AUTOSAR XML (schema 4-2-2)
package /STELLANTIS/EPT/ASWCs
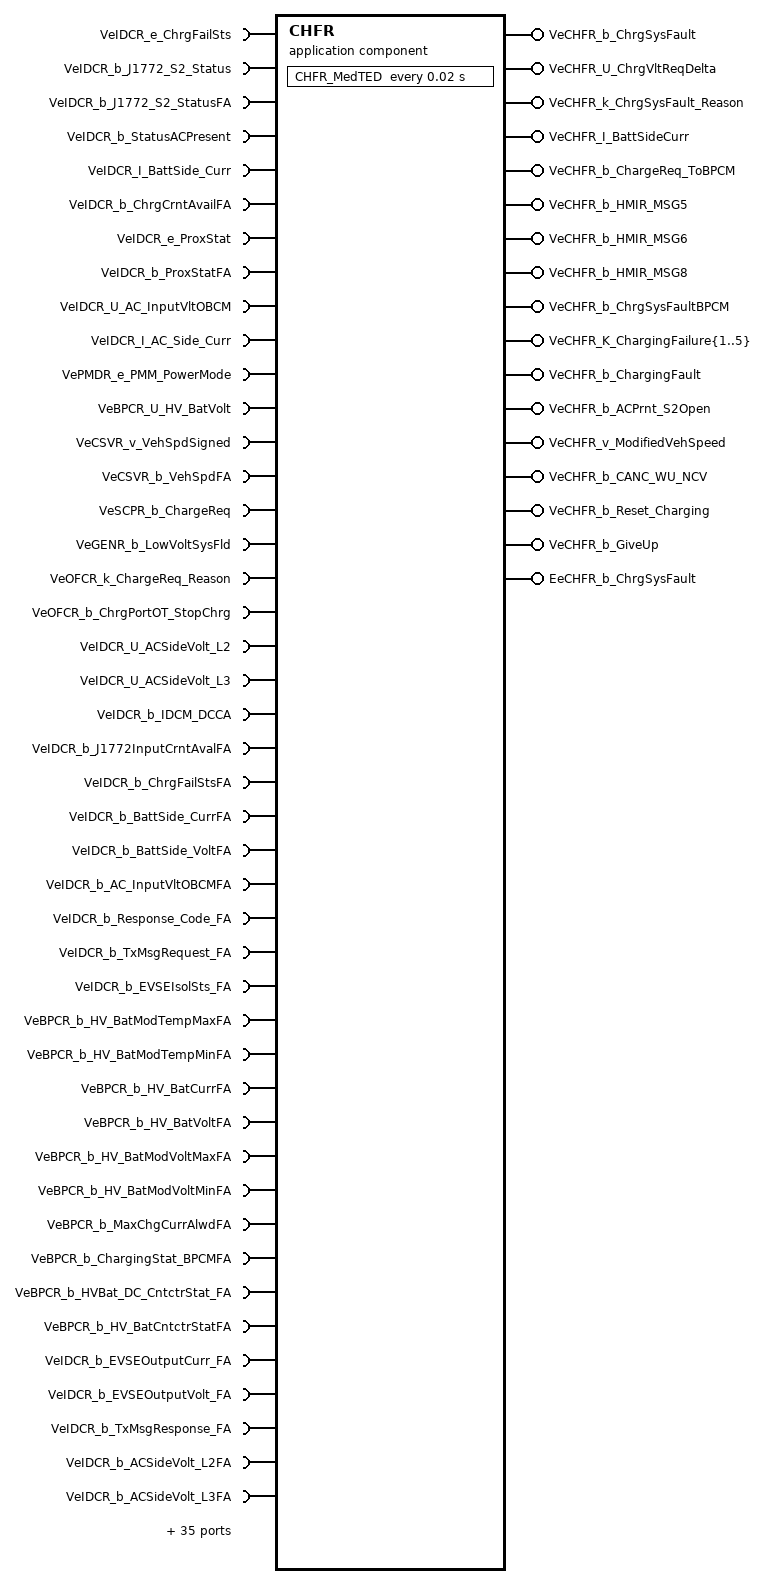
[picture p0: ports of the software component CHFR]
  application sw component type CHFR
    78 x require port:
      VeIDCR_e_ChrgFailSts: variation-point={short-label=vpVeIDCR_e_ChrgFailSts, sw-syscond=1}, nonqueued-receiver-com-spec{data-element=Value, init-value=CeOBCR_e_No_FLT}, required-interface=VeIDCR_e_ChrgFailSts
      VeIDCR_b_J1772_S2_Status: variation-point={short-label=vpVeIDCR_b_J1772_S2_Status, sw-syscond=1}, nonqueued-receiver-com-spec{data-element=Value, init-value=0}, required-interface=VeIDCR_b_J1772_S2_Status
      VeIDCR_b_J1772_S2_StatusFA: variation-point={short-label=vpVeIDCR_b_J1772_S2_StatusFA, sw-syscond=1}, nonqueued-receiver-com-spec{data-element=Value, init-value=0}, required-interface=VeIDCR_b_J1772_S2_StatusFA
      VeIDCR_b_StatusACPresent: variation-point={short-label=vpVeIDCR_b_StatusACPresent, sw-syscond=1}, nonqueued-receiver-com-spec{data-element=Value, init-value=0}, required-interface=VeIDCR_b_StatusACPresent
      VeIDCR_I_BattSide_Curr: variation-point={short-label=vpVeIDCR_I_BattSide_Curr, sw-syscond=1}, nonqueued-receiver-com-spec{data-element=Value, init-value=0}, required-interface=VeIDCR_I_BattSide_Curr
      VeIDCR_b_ChrgCrntAvailFA: variation-point={short-label=vpVeIDCR_b_ChrgCrntAvailFA, sw-syscond=1}, nonqueued-receiver-com-spec{data-element=Value, init-value=0}, required-interface=VeIDCR_b_ChrgCrntAvailFA
      VeIDCR_e_ProxStat: variation-point={short-label=vpVeIDCR_e_ProxStat, sw-syscond=1}, nonqueued-receiver-com-spec{data-element=Value, init-value=CeOBCR_e_ProxLo_OBCM}, required-interface=VeIDCR_e_ProxStat
      VeIDCR_b_ProxStatFA: variation-point={short-label=vpVeIDCR_b_ProxStatFA, sw-syscond=1}, nonqueued-receiver-com-spec{data-element=Value, init-value=0}, required-interface=VeIDCR_b_ProxStatFA
      VeIDCR_U_AC_InputVltOBCM: variation-point={short-label=vpVeIDCR_U_AC_InputVltOBCM, sw-syscond=1}, nonqueued-receiver-com-spec{data-element=Value, init-value=0}, required-interface=VeIDCR_U_AC_InputVltOBCM
      VeIDCR_I_AC_Side_Curr: variation-point={short-label=vpVeIDCR_I_AC_Side_Curr, sw-syscond=1}, nonqueued-receiver-com-spec{data-element=Value, init-value=0}, required-interface=VeIDCR_I_AC_Side_Curr
      VePMDR_e_PMM_PowerMode: variation-point={short-label=vpVePMDR_e_PMM_PowerMode, sw-syscond=1}, nonqueued-receiver-com-spec{data-element=Value, init-value=CePMDR_e_PowerMode_Off}, required-interface=VePMDR_e_PMM_PowerMode
      VeBPCR_U_HV_BatVolt: variation-point={short-label=vpVeBPCR_U_HV_BatVolt, sw-syscond=1}, nonqueued-receiver-com-spec{data-element=Value, init-value=0}, required-interface=VeBPCR_U_HV_BatVolt
      VeCSVR_v_VehSpdSigned: variation-point={short-label=vpVeCSVR_v_VehSpdSigned, sw-syscond=1}, nonqueued-receiver-com-spec{data-element=Value, init-value=0}, required-interface=VeCSVR_v_VehSpdSigned
      VeCSVR_b_VehSpdFA: variation-point={short-label=vpVeCSVR_b_VehSpdFA, sw-syscond=1}, nonqueued-receiver-com-spec{data-element=Value, init-value=0}, required-interface=VeCSVR_b_VehSpdFA
      VeSCPR_b_ChargeReq: variation-point={short-label=vpVeSCPR_b_ChargeReq, sw-syscond=1}, nonqueued-receiver-com-spec{data-element=Value, init-value=0}, required-interface=VeSCPR_b_ChargeReq
      VeGENR_b_LowVoltSysFld: variation-point={short-label=vpVeGENR_b_LowVoltSysFld, sw-syscond=1}, nonqueued-receiver-com-spec{data-element=Value, init-value=0}, required-interface=VeGENR_b_LowVoltSysFld
      VeOFCR_k_ChargeReq_Reason: variation-point={short-label=vpVeOFCR_k_ChargeReq_Reason, sw-syscond=1}, nonqueued-receiver-com-spec{data-element=Value, init-value=0}, required-interface=VeOFCR_k_ChargeReq_Reason
      VeOFCR_b_ChrgPortOT_StopChrg: variation-point={short-label=vpVeOFCR_b_ChrgPortOT_StopChrg, sw-syscond=1}, nonqueued-receiver-com-spec{data-element=Value, init-value=0}, required-interface=VeOFCR_b_ChrgPortOT_StopChrg
      VeIDCR_U_ACSideVolt_L2: variation-point={short-label=vpVeIDCR_U_ACSideVolt_L2, sw-syscond=1}, nonqueued-receiver-com-spec{data-element=Value, init-value=0}, required-interface=VeIDCR_U_ACSideVolt_L2
      VeIDCR_U_ACSideVolt_L3: variation-point={short-label=vpVeIDCR_U_ACSideVolt_L3, sw-syscond=1}, nonqueued-receiver-com-spec{data-element=Value, init-value=0}, required-interface=VeIDCR_U_ACSideVolt_L3
      VeIDCR_b_IDCM_DCCA: variation-point={short-label=vpVeIDCR_b_IDCM_DCCA, sw-syscond=1}, nonqueued-receiver-com-spec{data-element=Value, init-value=0}, required-interface=VeIDCR_b_IDCM_DCCA
      VeIDCR_b_J1772InputCrntAvalFA: variation-point={short-label=vpVeIDCR_b_J1772InputCrntAvalFA, sw-syscond=1}, nonqueued-receiver-com-spec{data-element=Value, init-value=0}, required-interface=VeIDCR_b_J1772InputCrntAvalFA
      VeIDCR_b_ChrgFailStsFA: variation-point={short-label=vpVeIDCR_b_ChrgFailStsFA, sw-syscond=1}, nonqueued-receiver-com-spec{data-element=Value, init-value=0}, required-interface=VeIDCR_b_ChrgFailStsFA
      VeIDCR_b_BattSide_CurrFA: variation-point={short-label=vpVeIDCR_b_BattSide_CurrFA, sw-syscond=1}, nonqueued-receiver-com-spec{data-element=Value, init-value=0}, required-interface=VeIDCR_b_BattSide_CurrFA
      VeIDCR_b_BattSide_VoltFA: variation-point={short-label=vpVeIDCR_b_BattSide_VoltFA, sw-syscond=1}, nonqueued-receiver-com-spec{data-element=Value, init-value=0}, required-interface=VeIDCR_b_BattSide_VoltFA
      VeIDCR_b_AC_InputVltOBCMFA: variation-point={short-label=vpVeIDCR_b_AC_InputVltOBCMFA, sw-syscond=1}, nonqueued-receiver-com-spec{data-element=Value, init-value=0}, required-interface=VeIDCR_b_AC_InputVltOBCMFA
      VeIDCR_b_Response_Code_FA: variation-point={short-label=vpVeIDCR_b_Response_Code_FA, sw-syscond=1}, nonqueued-receiver-com-spec{data-element=Value, init-value=0}, required-interface=VeIDCR_b_Response_Code_FA
      VeIDCR_b_TxMsgRequest_FA: variation-point={short-label=vpVeIDCR_b_TxMsgRequest_FA, sw-syscond=1}, nonqueued-receiver-com-spec{data-element=Value, init-value=0}, required-interface=VeIDCR_b_TxMsgRequest_FA
      VeIDCR_b_EVSEIsolSts_FA: variation-point={short-label=vpVeIDCR_b_EVSEIsolSts_FA, sw-syscond=1}, nonqueued-receiver-com-spec{data-element=Value, init-value=0}, required-interface=VeIDCR_b_EVSEIsolSts_FA
      VeBPCR_b_HV_BatModTempMaxFA: variation-point={short-label=vpVeBPCR_b_HV_BatModTempMaxFA, sw-syscond=1}, nonqueued-receiver-com-spec{data-element=Value, init-value=0}, required-interface=VeBPCR_b_HV_BatModTempMaxFA
      VeBPCR_b_HV_BatModTempMinFA: variation-point={short-label=vpVeBPCR_b_HV_BatModTempMinFA, sw-syscond=1}, nonqueued-receiver-com-spec{data-element=Value, init-value=0}, required-interface=VeBPCR_b_HV_BatModTempMinFA
      VeBPCR_b_HV_BatCurrFA: variation-point={short-label=vpVeBPCR_b_HV_BatCurrFA, sw-syscond=1}, nonqueued-receiver-com-spec{data-element=Value, init-value=0}, required-interface=VeBPCR_b_HV_BatCurrFA
      VeBPCR_b_HV_BatVoltFA: variation-point={short-label=vpVeBPCR_b_HV_BatVoltFA, sw-syscond=1}, nonqueued-receiver-com-spec{data-element=Value, init-value=0}, required-interface=VeBPCR_b_HV_BatVoltFA
      VeBPCR_b_HV_BatModVoltMaxFA: variation-point={short-label=vpVeBPCR_b_HV_BatModVoltMaxFA, sw-syscond=1}, nonqueued-receiver-com-spec{data-element=Value, init-value=0}, required-interface=VeBPCR_b_HV_BatModVoltMaxFA
      VeBPCR_b_HV_BatModVoltMinFA: variation-point={short-label=vpVeBPCR_b_HV_BatModVoltMinFA, sw-syscond=1}, nonqueued-receiver-com-spec{data-element=Value, init-value=0}, required-interface=VeBPCR_b_HV_BatModVoltMinFA
      VeBPCR_b_MaxChgCurrAlwdFA: variation-point={short-label=vpVeBPCR_b_MaxChgCurrAlwdFA, sw-syscond=1}, nonqueued-receiver-com-spec{data-element=Value, init-value=0}, required-interface=VeBPCR_b_MaxChgCurrAlwdFA
      VeBPCR_b_ChargingStat_BPCMFA: variation-point={short-label=vpVeBPCR_b_ChargingStat_BPCMFA, sw-syscond=1}, nonqueued-receiver-com-spec{data-element=Value, init-value=0}, required-interface=VeBPCR_b_ChargingStat_BPCMFA
      VeBPCR_b_HVBat_DC_CntctrStat_FA: variation-point={short-label=vpVeBPCR_b_HVBat_DC_CntctrStat_FA, sw-syscond=1}, nonqueued-receiver-com-spec{data-element=Value, init-value=0}, required-interface=VeBPCR_b_HVBat_DC_CntctrStat_FA
      VeBPCR_b_HV_BatCntctrStatFA: variation-point={short-label=vpVeBPCR_b_HV_BatCntctrStatFA, sw-syscond=1}, nonqueued-receiver-com-spec{data-element=Value, init-value=0}, required-interface=VeBPCR_b_HV_BatCntctrStatFA
      VeIDCR_b_EVSEOutputCurr_FA: variation-point={short-label=vpVeIDCR_b_EVSEOutputCurr_FA, sw-syscond=1}, nonqueued-receiver-com-spec{data-element=Value, init-value=0}, required-interface=VeIDCR_b_EVSEOutputCurr_FA
      VeIDCR_b_EVSEOutputVolt_FA: variation-point={short-label=vpVeIDCR_b_EVSEOutputVolt_FA, sw-syscond=1}, nonqueued-receiver-com-spec{data-element=Value, init-value=0}, required-interface=VeIDCR_b_EVSEOutputVolt_FA
      VeIDCR_b_TxMsgResponse_FA: variation-point={short-label=vpVeIDCR_b_TxMsgResponse_FA, sw-syscond=1}, nonqueued-receiver-com-spec{data-element=Value, init-value=0}, required-interface=VeIDCR_b_TxMsgResponse_FA
      VeIDCR_b_ACSideVolt_L2FA: variation-point={short-label=vpVeIDCR_b_ACSideVolt_L2FA, sw-syscond=1}, nonqueued-receiver-com-spec{data-element=Value, init-value=0}, required-interface=VeIDCR_b_ACSideVolt_L2FA
      VeIDCR_b_ACSideVolt_L3FA: variation-point={short-label=vpVeIDCR_b_ACSideVolt_L3FA, sw-syscond=1}, nonqueued-receiver-com-spec{data-element=Value, init-value=0}, required-interface=VeIDCR_b_ACSideVolt_L3FA
      VeIDCR_e_V2L_DischargeFailSts: variation-point={short-label=vpVeIDCR_e_V2L_DischargeFailSts, sw-syscond=1}, nonqueued-receiver-com-spec{data-element=Value, init-value=CeVTLR_e_No_Fault}, required-interface=VeIDCR_e_V2L_DischargeFailSts
      VeIDCR_b_V2L_DischargeFailStsFA: variation-point={short-label=vpVeIDCR_b_V2L_DischargeFailStsFA, sw-syscond=1}, nonqueued-receiver-com-spec{data-element=Value, init-value=0}, required-interface=VeIDCR_b_V2L_DischargeFailStsFA
      VeDMAB_y_StatusByte_CtrlPilotCkt: variation-point={short-label=vpVeDMAB_y_StatusByte_CtrlPilotCkt, sw-syscond=1}, nonqueued-receiver-com-spec{data-element=Value, init-value=0}, required-interface=VeDMAB_y_StatusByte_CtrlPilotCkt
      VeDMAB_y_StatusByte_LosCommBECM_A_CANC11: variation-point={short-label=vpVeDMAB_y_StatusByte_LosCommBECM_A_CANC11, sw-syscond=1}, nonqueued-receiver-com-spec{data-element=Value, init-value=0}, required-interface=VeDMAB_y_StatusByte_LosCommBECM_A_CANC11
      VeDMAB_y_StatusByte_LosCommBECM_A: variation-point={short-label=vpVeDMAB_y_StatusByte_LosCommBECM_A, sw-syscond=1}, nonqueued-receiver-com-spec{data-element=Value, init-value=0}, required-interface=VeDMAB_y_StatusByte_LosCommBECM_A
      VeBPCR_b_DCIsolStsFA: variation-point={short-label=vpVeBPCR_b_DCIsolStsFA, sw-syscond=1}, nonqueued-receiver-com-spec{data-element=Value, init-value=0}, required-interface=VeBPCR_b_DCIsolStsFA
      VeBPCR_b_HV_SeriesVoltFA: variation-point={short-label=vpVeBPCR_b_HV_SeriesVoltFA, sw-syscond=1}, nonqueued-receiver-com-spec{data-element=Value, init-value=0}, required-interface=VeBPCR_b_HV_SeriesVoltFA
      VeBPCR_b_HV_AuxLoadOffReqFA: variation-point={short-label=vpVeBPCR_b_HV_AuxLoadOffReqFA, sw-syscond=1}, nonqueued-receiver-com-spec{data-element=Value, init-value=0}, required-interface=VeBPCR_b_HV_AuxLoadOffReqFA
      VaHPMR_K_RsnForUnintndShtDwn1: variation-point={short-label=vpVaHPMR_K_RsnForUnintndShtDwn1, sw-syscond=1}, nonqueued-receiver-com-spec{data-element=Value, init-value=15 x 0}, required-interface=VaHPMR_K_RsnForUnintndShtDwn1
      VaHPMR_K_RsnForUnintndShtDwn2: variation-point={short-label=vpVaHPMR_K_RsnForUnintndShtDwn2, sw-syscond=1}, nonqueued-receiver-com-spec{data-element=Value, init-value=15 x 0}, required-interface=VaHPMR_K_RsnForUnintndShtDwn2
      VaOBCR_b_NCR_Signals: variation-point={short-label=vpVaOBCR_b_NCR_Signals, sw-syscond=1}, nonqueued-receiver-com-spec{data-element=Value, init-value=15 x 0}, required-interface=VaOBCR_b_NCR_Signals
      VeSRAR_k_ReasonStopCharging: variation-point={short-label=vpVeSRAR_k_ReasonStopCharging, sw-syscond=1}, nonqueued-receiver-com-spec{data-element=Value, init-value=0}, required-interface=VeSRAR_k_ReasonStopCharging
      VeHPMR_e_RsnForUnintndShtDwn: variation-point={short-label=vpVeHPMR_e_RsnForUnintndShtDwn, sw-syscond=1}, nonqueued-receiver-com-spec{data-element=Value, init-value=CeHPMR_e_NoUnintndShtDwn}, required-interface=VeHPMR_e_RsnForUnintndShtDwn
      VeOBCR_Cnt_NCR: variation-point={short-label=vpVeOBCR_Cnt_NCR, sw-syscond=1}, nonqueued-receiver-com-spec{data-element=Value, init-value=0}, required-interface=VeOBCR_Cnt_NCR
      VeOBCR_e_ChrgSysStat_SF: variation-point={short-label=vpVeOBCR_e_ChrgSysStat_SF, sw-syscond=1}, nonqueued-receiver-com-spec{data-element=Value, init-value=CeOBCR_e_PowerUp}, required-interface=VeOBCR_e_ChrgSysStat_SF
      VeOBCR_Cnt_PlugIn_Reason: variation-point={short-label=vpVeOBCR_Cnt_PlugIn_Reason, sw-syscond=1}, nonqueued-receiver-com-spec{data-element=Value, init-value=0}, required-interface=VeOBCR_Cnt_PlugIn_Reason
      VeOBCR_Cnt_InitChecks_Reason: variation-point={short-label=vpVeOBCR_Cnt_InitChecks_Reason, sw-syscond=1}, nonqueued-receiver-com-spec{data-element=Value, init-value=0}, required-interface=VeOBCR_Cnt_InitChecks_Reason
      VeOBCR_b_EnablePowerTransfer: variation-point={short-label=vpVeOBCR_b_EnablePowerTransfer, sw-syscond=1}, nonqueued-receiver-com-spec{data-element=Value, init-value=0}, required-interface=VeOBCR_b_EnablePowerTransfer
      VeDCCR_k_DCExitRsn_SF: variation-point={short-label=vpVeDCCR_k_DCExitRsn_SF, sw-syscond=1}, nonqueued-receiver-com-spec{data-element=Value, init-value=0}, required-interface=VeDCCR_k_DCExitRsn_SF
      VaOBCR_Cnt_PlugIn_Vector: variation-point={short-label=vpVaOBCR_Cnt_PlugIn_Vector, sw-syscond=1}, nonqueued-receiver-com-spec{data-element=Value, init-value=15 x 0}, required-interface=VaOBCR_Cnt_PlugIn_Vector
      VaOBCR_k_InitChecks_Vector: variation-point={short-label=vpVaOBCR_k_InitChecks_Vector, sw-syscond=1}, nonqueued-receiver-com-spec{data-element=Value, init-value=7 x 0}, required-interface=VaOBCR_k_InitChecks_Vector
      VeOBCR_b_PluggedIn: variation-point={short-label=vpVeOBCR_b_PluggedIn, sw-syscond=1}, nonqueued-receiver-com-spec{data-element=Value, init-value=0}, required-interface=VeOBCR_b_PluggedIn
      VeCCCR_b_ChrgCmplteCondtnMet: variation-point={short-label=vpVeCCCR_b_ChrgCmplteCondtnMet, sw-syscond=1}, nonqueued-receiver-com-spec{data-element=Value, init-value=0}, required-interface=VeCCCR_b_ChrgCmplteCondtnMet
      VeOBCR_e_ChargingLevel: variation-point={short-label=vpVeOBCR_e_ChargingLevel, sw-syscond=1}, nonqueued-receiver-com-spec{data-element=Value, init-value=CeOBCR_e_ChargingLvlDefault}, required-interface=VeOBCR_e_ChargingLevel
      VeCPLR_b_ChargPortFault: variation-point={short-label=vpVeCPLR_b_ChargPortFault, sw-syscond=1}, nonqueued-receiver-com-spec{data-element=Value, init-value=0}, required-interface=VeCPLR_b_ChargPortFault
      VeOBCR_P_AvalPwrForThmr: variation-point={short-label=vpVeOBCR_P_AvalPwrForThmr, sw-syscond=1}, nonqueued-receiver-com-spec{data-element=Value, init-value=0}, required-interface=VeOBCR_P_AvalPwrForThmr
      VeCCCR_U_VoltRq: variation-point={short-label=vpVeCCCR_U_VoltRq, sw-syscond=1}, nonqueued-receiver-com-spec{data-element=Value, init-value=0}, required-interface=VeCCCR_U_VoltRq
      VeCPLR_b_RelockTimerActive: variation-point={short-label=vpVeCPLR_b_RelockTimerActive, sw-syscond=1}, nonqueued-receiver-com-spec{data-element=Value, init-value=0}, required-interface=VeCPLR_b_RelockTimerActive
      VeOBCR_b_SmartEvse_Dtctd: variation-point={short-label=vpVeOBCR_b_SmartEvse_Dtctd, sw-syscond=1}, nonqueued-receiver-com-spec{data-element=Value, init-value=0}, required-interface=VeOBCR_b_SmartEvse_Dtctd
      VeOBCR_e_ChargeType: variation-point={short-label=vpVeOBCR_e_ChargeType, sw-syscond=1}, nonqueued-receiver-com-spec{data-element=Value, init-value=CeOBCR_e_AC}, required-interface=VeOBCR_e_ChargeType
      VeOBCR_b_ChrgrLOC: variation-point={short-label=vpVeOBCR_b_ChrgrLOC, sw-syscond=1}, nonqueued-receiver-com-spec{data-element=Value, init-value=0}, required-interface=VeOBCR_b_ChrgrLOC
      VeOBCR_b_SecureConnV2L: variation-point={short-label=vpVeOBCR_b_SecureConnV2L, sw-syscond=1}, nonqueued-receiver-com-spec{data-element=Value, init-value=0}, required-interface=VeOBCR_b_SecureConnV2L
      VeOBCR_b_EnblDsblProxPlg: variation-point={short-label=vpVeOBCR_b_EnblDsblProxPlg, sw-syscond=1}, nonqueued-receiver-com-spec{data-element=Value, init-value=0}, required-interface=VeOBCR_b_EnblDsblProxPlg
      VeGENR_b_IDCMThrmlRunAway: variation-point={short-label=vpVeGENR_b_IDCMThrmlRunAway, sw-syscond=1}, nonqueued-receiver-com-spec{data-element=Value, init-value=0}, required-interface=VeGENR_b_IDCMThrmlRunAway
    20 x provide port, all with nonqueued-sender-com-spec{data-element=Value, init-value=0}:
      VeCHFR_b_ChrgSysFault: provided-interface=VeCHFR_b_ChrgSysFault
      VeCHFR_U_ChrgVltReqDelta: provided-interface=VeCHFR_U_ChrgVltReqDelta
      VeCHFR_k_ChrgSysFault_Reason: provided-interface=VeCHFR_k_ChrgSysFault_Reason
      VeCHFR_I_BattSideCurr: provided-interface=VeCHFR_I_BattSideCurr
      VeCHFR_b_ChargeReq_ToBPCM: provided-interface=VeCHFR_b_ChargeReq_ToBPCM
      VeCHFR_b_HMIR_MSG5: provided-interface=VeCHFR_b_HMIR_MSG5
      VeCHFR_b_HMIR_MSG6: provided-interface=VeCHFR_b_HMIR_MSG6
      VeCHFR_b_HMIR_MSG8: provided-interface=VeCHFR_b_HMIR_MSG8
      VeCHFR_b_ChrgSysFaultBPCM: provided-interface=VeCHFR_b_ChrgSysFaultBPCM
      VeCHFR_K_ChargingFailure{1..5}: provided-interface=VeCHFR_K_ChargingFailure{1..5}
      VeCHFR_b_ChargingFault: provided-interface=VeCHFR_b_ChargingFault
      VeCHFR_b_ACPrnt_S2Open: provided-interface=VeCHFR_b_ACPrnt_S2Open
      VeCHFR_v_ModifiedVehSpeed: provided-interface=VeCHFR_v_ModifiedVehSpeed
      VeCHFR_b_CANC_WU_NCV: provided-interface=VeCHFR_b_CANC_WU_NCV
      VeCHFR_b_Reset_Charging: provided-interface=VeCHFR_b_Reset_Charging
      VeCHFR_b_GiveUp: provided-interface=VeCHFR_b_GiveUp
    require port EeCHFR_b_ChrgSysFault_Rx: variation-point={short-label=vpEeCHFR_b_ChrgSysFault_Rx, sw-syscond=1}, nv-require-com-spec{init-value=0, variable=EeCHFR_b_ChrgSysFault}, required-interface=EeCHFR_b_ChrgSysFault
    provide port EeCHFR_b_ChrgSysFault: variation-point={short-label=vpEeCHFR_b_ChrgSysFault, sw-syscond=1}, nv-provide-com-spec{ram-block-init-value=0, variable=EeCHFR_b_ChrgSysFault}, provided-interface=EeCHFR_b_ChrgSysFault
    behavior IB_CHFR: data-type-mapping=msADTtoIDTMapping, handle-termination-and-restart=NO-SUPPORT
      timing event Event_MedTED: start-on-event=CHFR_MedTED, period=0.02
      init event Event_CHFR_ac_Init: start-on-event=CHFR_ac_Init
      init event Event_PwrOn: start-on-event=CHFR_PwrOn
      init event Event_PwrOff: start-on-event=CHFR_PwrOff
      4 x runnable:
        CHFR_ac_Init
        CHFR_PwrOn
          data-receive-point-by-arguments:
            access IN_EeCHFR_b_ChrgSysFault_Rx_EeCHFR_b_ChrgSysFault: accessed-variable=EeCHFR_b_ChrgSysFault_Rx.EeCHFR_b_ChrgSysFault, variation-point={short-label=vpIN_EeCHFR_b_ChrgSysFault_Rx_EeCHFR_b_ChrgSysFault, sw-syscond=1}
          data-send-points:
            20 x access:
              OUT_VeCHFR_b_ChrgSysFault_Value: accessed-variable=VeCHFR_b_ChrgSysFault.Value
              OUT_VeCHFR_U_ChrgVltReqDelta_Value: accessed-variable=VeCHFR_U_ChrgVltReqDelta.Value
              OUT_VeCHFR_k_ChrgSysFault_Reason_Value: accessed-variable=VeCHFR_k_ChrgSysFault_Reason.Value
              OUT_VeCHFR_I_BattSideCurr_Value: accessed-variable=VeCHFR_I_BattSideCurr.Value
              OUT_VeCHFR_b_ChargeReq_ToBPCM_Value: accessed-variable=VeCHFR_b_ChargeReq_ToBPCM.Value
              OUT_VeCHFR_b_HMIR_MSG5_Value: accessed-variable=VeCHFR_b_HMIR_MSG5.Value
              OUT_VeCHFR_b_HMIR_MSG6_Value: accessed-variable=VeCHFR_b_HMIR_MSG6.Value
              OUT_VeCHFR_b_HMIR_MSG8_Value: accessed-variable=VeCHFR_b_HMIR_MSG8.Value
              OUT_VeCHFR_b_ChrgSysFaultBPCM_Value: accessed-variable=VeCHFR_b_ChrgSysFaultBPCM.Value
              OUT_VeCHFR_K_ChargingFailure{1..5}_Value: accessed-variable=VeCHFR_K_ChargingFailure{1..5}.Value
              OUT_VeCHFR_b_ChargingFault_Value: accessed-variable=VeCHFR_b_ChargingFault.Value
              OUT_VeCHFR_b_ACPrnt_S2Open_Value: accessed-variable=VeCHFR_b_ACPrnt_S2Open.Value
              OUT_VeCHFR_v_ModifiedVehSpeed_Value: accessed-variable=VeCHFR_v_ModifiedVehSpeed.Value
              OUT_VeCHFR_b_CANC_WU_NCV_Value: accessed-variable=VeCHFR_b_CANC_WU_NCV.Value
              OUT_VeCHFR_b_Reset_Charging_Value: accessed-variable=VeCHFR_b_Reset_Charging.Value
              OUT_VeCHFR_b_GiveUp_Value: accessed-variable=VeCHFR_b_GiveUp.Value
        CHFR_MedTED: variation-point={short-label=vpCHFR_MedTED, sw-syscond=1}
          data-receive-point-by-arguments:
            76 x access:
              IN_VaHPMR_K_RsnForUnintndShtDwn1_Value: accessed-variable=VaHPMR_K_RsnForUnintndShtDwn1.Value, variation-point={short-label=vpIN_VaHPMR_K_RsnForUnintndShtDwn1_Value, sw-syscond=1}
              IN_VaHPMR_K_RsnForUnintndShtDwn2_Value: accessed-variable=VaHPMR_K_RsnForUnintndShtDwn2.Value, variation-point={short-label=vpIN_VaHPMR_K_RsnForUnintndShtDwn2_Value, sw-syscond=1}
              IN_VaOBCR_Cnt_PlugIn_Vector_Value: accessed-variable=VaOBCR_Cnt_PlugIn_Vector.Value, variation-point={short-label=vpIN_VaOBCR_Cnt_PlugIn_Vector_Value, sw-syscond=1}
              IN_VaOBCR_b_NCR_Signals_Value: accessed-variable=VaOBCR_b_NCR_Signals.Value, variation-point={short-label=vpIN_VaOBCR_b_NCR_Signals_Value, sw-syscond=1}
              IN_VaOBCR_k_InitChecks_Vector_Value: accessed-variable=VaOBCR_k_InitChecks_Vector.Value, variation-point={short-label=vpIN_VaOBCR_k_InitChecks_Vector_Value, sw-syscond=1}
              IN_VeBPCR_U_HV_BatVolt_Value: accessed-variable=VeBPCR_U_HV_BatVolt.Value, variation-point={short-label=vpIN_VeBPCR_U_HV_BatVolt_Value, sw-syscond=1}
              IN_VeBPCR_b_ChargingStat_BPCMFA_Value: accessed-variable=VeBPCR_b_ChargingStat_BPCMFA.Value, variation-point={short-label=vpIN_VeBPCR_b_ChargingStat_BPCMFA_Value, sw-syscond=1}
              IN_VeBPCR_b_DCIsolStsFA_Value: accessed-variable=VeBPCR_b_DCIsolStsFA.Value, variation-point={short-label=vpIN_VeBPCR_b_DCIsolStsFA_Value, sw-syscond=1}
              IN_VeBPCR_b_HVBat_DC_CntctrStat_FA_Value: accessed-variable=VeBPCR_b_HVBat_DC_CntctrStat_FA.Value, variation-point={short-label=vpIN_VeBPCR_b_HVBat_DC_CntctrStat_FA_Value, sw-syscond=1}
              IN_VeBPCR_b_HV_AuxLoadOffReqFA_Value: accessed-variable=VeBPCR_b_HV_AuxLoadOffReqFA.Value, variation-point={short-label=vpIN_VeBPCR_b_HV_AuxLoadOffReqFA_Value, sw-syscond=1}
              IN_VeBPCR_b_HV_BatCntctrStatFA_Value: accessed-variable=VeBPCR_b_HV_BatCntctrStatFA.Value, variation-point={short-label=vpIN_VeBPCR_b_HV_BatCntctrStatFA_Value, sw-syscond=1}
              IN_VeBPCR_b_HV_BatCurrFA_Value: accessed-variable=VeBPCR_b_HV_BatCurrFA.Value, variation-point={short-label=vpIN_VeBPCR_b_HV_BatCurrFA_Value, sw-syscond=1}
              IN_VeBPCR_b_HV_BatModTempMaxFA_Value: accessed-variable=VeBPCR_b_HV_BatModTempMaxFA.Value, variation-point={short-label=vpIN_VeBPCR_b_HV_BatModTempMaxFA_Value, sw-syscond=1}
              IN_VeBPCR_b_HV_BatModTempMinFA_Value: accessed-variable=VeBPCR_b_HV_BatModTempMinFA.Value, variation-point={short-label=vpIN_VeBPCR_b_HV_BatModTempMinFA_Value, sw-syscond=1}
              IN_VeBPCR_b_HV_BatModVoltMaxFA_Value: accessed-variable=VeBPCR_b_HV_BatModVoltMaxFA.Value, variation-point={short-label=vpIN_VeBPCR_b_HV_BatModVoltMaxFA_Value, sw-syscond=1}
              IN_VeBPCR_b_HV_BatModVoltMinFA_Value: accessed-variable=VeBPCR_b_HV_BatModVoltMinFA.Value, variation-point={short-label=vpIN_VeBPCR_b_HV_BatModVoltMinFA_Value, sw-syscond=1}
              IN_VeBPCR_b_HV_BatVoltFA_Value: accessed-variable=VeBPCR_b_HV_BatVoltFA.Value, variation-point={short-label=vpIN_VeBPCR_b_HV_BatVoltFA_Value, sw-syscond=1}
              IN_VeBPCR_b_HV_SeriesVoltFA_Value: accessed-variable=VeBPCR_b_HV_SeriesVoltFA.Value, variation-point={short-label=vpIN_VeBPCR_b_HV_SeriesVoltFA_Value, sw-syscond=1}
              IN_VeBPCR_b_MaxChgCurrAlwdFA_Value: accessed-variable=VeBPCR_b_MaxChgCurrAlwdFA.Value, variation-point={short-label=vpIN_VeBPCR_b_MaxChgCurrAlwdFA_Value, sw-syscond=1}
              IN_VeCCCR_U_VoltRq_Value: accessed-variable=VeCCCR_U_VoltRq.Value, variation-point={short-label=vpIN_VeCCCR_U_VoltRq_Value, sw-syscond=1}
              IN_VeCCCR_b_ChrgCmplteCondtnMet_Value: accessed-variable=VeCCCR_b_ChrgCmplteCondtnMet.Value, variation-point={short-label=vpIN_VeCCCR_b_ChrgCmplteCondtnMet_Value, sw-syscond=1}
              IN_VeCPLR_b_ChargPortFault_Value: accessed-variable=VeCPLR_b_ChargPortFault.Value, variation-point={short-label=vpIN_VeCPLR_b_ChargPortFault_Value, sw-syscond=1}
              IN_VeCPLR_b_RelockTimerActive_Value: accessed-variable=VeCPLR_b_RelockTimerActive.Value, variation-point={short-label=vpIN_VeCPLR_b_RelockTimerActive_Value, sw-syscond=1}
              IN_VeCSVR_b_VehSpdFA_Value: accessed-variable=VeCSVR_b_VehSpdFA.Value, variation-point={short-label=vpIN_VeCSVR_b_VehSpdFA_Value, sw-syscond=1}
              IN_VeCSVR_v_VehSpdSigned_Value: accessed-variable=VeCSVR_v_VehSpdSigned.Value, variation-point={short-label=vpIN_VeCSVR_v_VehSpdSigned_Value, sw-syscond=1}
              IN_VeDCCR_k_DCExitRsn_SF_Value: accessed-variable=VeDCCR_k_DCExitRsn_SF.Value, variation-point={short-label=vpIN_VeDCCR_k_DCExitRsn_SF_Value, sw-syscond=1}
              IN_VeDMAB_y_StatusByte_CtrlPilotCkt_Value: accessed-variable=VeDMAB_y_StatusByte_CtrlPilotCkt.Value, variation-point={short-label=vpIN_VeDMAB_y_StatusByte_CtrlPilotCkt_Value, sw-syscond=1}
              IN_VeDMAB_y_StatusByte_LosCommBECM_A_Value: accessed-variable=VeDMAB_y_StatusByte_LosCommBECM_A.Value, variation-point={short-label=vpIN_VeDMAB_y_StatusByte_LosCommBECM_A_Value, sw-syscond=1}
              IN_VeDMAB_y_StatusByte_LosCommBECM_A_CANC11_Value: accessed-variable=VeDMAB_y_StatusByte_LosCommBECM_A_CANC11.Value, variation-point={short-label=vpIN_VeDMAB_y_StatusByte_LosCommBECM_A_CANC11_Value, sw-syscond=1}
              IN_VeGENR_b_IDCMThrmlRunAway_Value: accessed-variable=VeGENR_b_IDCMThrmlRunAway.Value, variation-point={short-label=vpIN_VeGENR_b_IDCMThrmlRunAway_Value, sw-syscond=1}
              IN_VeGENR_b_LowVoltSysFld_Value: accessed-variable=VeGENR_b_LowVoltSysFld.Value, variation-point={short-label=vpIN_VeGENR_b_LowVoltSysFld_Value, sw-syscond=1}
              IN_VeHPMR_e_RsnForUnintndShtDwn_Value: accessed-variable=VeHPMR_e_RsnForUnintndShtDwn.Value, variation-point={short-label=vpIN_VeHPMR_e_RsnForUnintndShtDwn_Value, sw-syscond=1}
              IN_VeIDCR_I_AC_Side_Curr_Value: accessed-variable=VeIDCR_I_AC_Side_Curr.Value, variation-point={short-label=vpIN_VeIDCR_I_AC_Side_Curr_Value, sw-syscond=1}
              IN_VeIDCR_I_BattSide_Curr_Value: accessed-variable=VeIDCR_I_BattSide_Curr.Value, variation-point={short-label=vpIN_VeIDCR_I_BattSide_Curr_Value, sw-syscond=1}
              IN_VeIDCR_U_AC_InputVltOBCM_Value: accessed-variable=VeIDCR_U_AC_InputVltOBCM.Value, variation-point={short-label=vpIN_VeIDCR_U_AC_InputVltOBCM_Value, sw-syscond=1}
              IN_VeIDCR_b_ACSideVolt_L2FA_Value: accessed-variable=VeIDCR_b_ACSideVolt_L2FA.Value, variation-point={short-label=vpIN_VeIDCR_b_ACSideVolt_L2FA_Value, sw-syscond=1}
              IN_VeIDCR_b_ACSideVolt_L3FA_Value: accessed-variable=VeIDCR_b_ACSideVolt_L3FA.Value, variation-point={short-label=vpIN_VeIDCR_b_ACSideVolt_L3FA_Value, sw-syscond=1}
              IN_VeIDCR_b_AC_InputVltOBCMFA_Value: accessed-variable=VeIDCR_b_AC_InputVltOBCMFA.Value, variation-point={short-label=vpIN_VeIDCR_b_AC_InputVltOBCMFA_Value, sw-syscond=1}
              IN_VeIDCR_b_BattSide_CurrFA_Value: accessed-variable=VeIDCR_b_BattSide_CurrFA.Value, variation-point={short-label=vpIN_VeIDCR_b_BattSide_CurrFA_Value, sw-syscond=1}
              IN_VeIDCR_b_BattSide_VoltFA_Value: accessed-variable=VeIDCR_b_BattSide_VoltFA.Value, variation-point={short-label=vpIN_VeIDCR_b_BattSide_VoltFA_Value, sw-syscond=1}
              IN_VeIDCR_b_ChrgCrntAvailFA_Value: accessed-variable=VeIDCR_b_ChrgCrntAvailFA.Value, variation-point={short-label=vpIN_VeIDCR_b_ChrgCrntAvailFA_Value, sw-syscond=1}
              IN_VeIDCR_b_ChrgFailStsFA_Value: accessed-variable=VeIDCR_b_ChrgFailStsFA.Value, variation-point={short-label=vpIN_VeIDCR_b_ChrgFailStsFA_Value, sw-syscond=1}
              IN_VeIDCR_b_EVSEIsolSts_FA_Value: accessed-variable=VeIDCR_b_EVSEIsolSts_FA.Value, variation-point={short-label=vpIN_VeIDCR_b_EVSEIsolSts_FA_Value, sw-syscond=1}
              IN_VeIDCR_b_EVSEOutputCurr_FA_Value: accessed-variable=VeIDCR_b_EVSEOutputCurr_FA.Value, variation-point={short-label=vpIN_VeIDCR_b_EVSEOutputCurr_FA_Value, sw-syscond=1}
              IN_VeIDCR_b_EVSEOutputVolt_FA_Value: accessed-variable=VeIDCR_b_EVSEOutputVolt_FA.Value, variation-point={short-label=vpIN_VeIDCR_b_EVSEOutputVolt_FA_Value, sw-syscond=1}
              IN_VeIDCR_b_IDCM_DCCA_Value: accessed-variable=VeIDCR_b_IDCM_DCCA.Value, variation-point={short-label=vpIN_VeIDCR_b_IDCM_DCCA_Value, sw-syscond=1}
              IN_VeIDCR_b_J1772InputCrntAvalFA_Value: accessed-variable=VeIDCR_b_J1772InputCrntAvalFA.Value, variation-point={short-label=vpIN_VeIDCR_b_J1772InputCrntAvalFA_Value, sw-syscond=1}
              IN_VeIDCR_b_J1772_S2_Status_Value: accessed-variable=VeIDCR_b_J1772_S2_Status.Value, variation-point={short-label=vpIN_VeIDCR_b_J1772_S2_Status_Value, sw-syscond=1}
              IN_VeIDCR_b_J1772_S2_StatusFA_Value: accessed-variable=VeIDCR_b_J1772_S2_StatusFA.Value, variation-point={short-label=vpIN_VeIDCR_b_J1772_S2_StatusFA_Value, sw-syscond=1}
              IN_VeIDCR_b_ProxStatFA_Value: accessed-variable=VeIDCR_b_ProxStatFA.Value, variation-point={short-label=vpIN_VeIDCR_b_ProxStatFA_Value, sw-syscond=1}
              IN_VeIDCR_b_Response_Code_FA_Value: accessed-variable=VeIDCR_b_Response_Code_FA.Value, variation-point={short-label=vpIN_VeIDCR_b_Response_Code_FA_Value, sw-syscond=1}
              IN_VeIDCR_b_StatusACPresent_Value: accessed-variable=VeIDCR_b_StatusACPresent.Value, variation-point={short-label=vpIN_VeIDCR_b_StatusACPresent_Value, sw-syscond=1}
              IN_VeIDCR_b_TxMsgRequest_FA_Value: accessed-variable=VeIDCR_b_TxMsgRequest_FA.Value, variation-point={short-label=vpIN_VeIDCR_b_TxMsgRequest_FA_Value, sw-syscond=1}
              IN_VeIDCR_b_TxMsgResponse_FA_Value: accessed-variable=VeIDCR_b_TxMsgResponse_FA.Value, variation-point={short-label=vpIN_VeIDCR_b_TxMsgResponse_FA_Value, sw-syscond=1}
              IN_VeIDCR_b_V2L_DischargeFailStsFA_Value: accessed-variable=VeIDCR_b_V2L_DischargeFailStsFA.Value, variation-point={short-label=vpIN_VeIDCR_b_V2L_DischargeFailStsFA_Value, sw-syscond=1}
              IN_VeIDCR_e_ChrgFailSts_Value: accessed-variable=VeIDCR_e_ChrgFailSts.Value, variation-point={short-label=vpIN_VeIDCR_e_ChrgFailSts_Value, sw-syscond=1}
              IN_VeIDCR_e_ProxStat_Value: accessed-variable=VeIDCR_e_ProxStat.Value, variation-point={short-label=vpIN_VeIDCR_e_ProxStat_Value, sw-syscond=1}
              IN_VeIDCR_e_V2L_DischargeFailSts_Value: accessed-variable=VeIDCR_e_V2L_DischargeFailSts.Value, variation-point={short-label=vpIN_VeIDCR_e_V2L_DischargeFailSts_Value, sw-syscond=1}
              IN_VeOBCR_Cnt_InitChecks_Reason_Value: accessed-variable=VeOBCR_Cnt_InitChecks_Reason.Value, variation-point={short-label=vpIN_VeOBCR_Cnt_InitChecks_Reason_Value, sw-syscond=1}
              IN_VeOBCR_Cnt_NCR_Value: accessed-variable=VeOBCR_Cnt_NCR.Value, variation-point={short-label=vpIN_VeOBCR_Cnt_NCR_Value, sw-syscond=1}
              IN_VeOBCR_Cnt_PlugIn_Reason_Value: accessed-variable=VeOBCR_Cnt_PlugIn_Reason.Value, variation-point={short-label=vpIN_VeOBCR_Cnt_PlugIn_Reason_Value, sw-syscond=1}
              IN_VeOBCR_P_AvalPwrForThmr_Value: accessed-variable=VeOBCR_P_AvalPwrForThmr.Value, variation-point={short-label=vpIN_VeOBCR_P_AvalPwrForThmr_Value, sw-syscond=1}
              IN_VeOBCR_b_ChrgrLOC_Value: accessed-variable=VeOBCR_b_ChrgrLOC.Value, variation-point={short-label=vpIN_VeOBCR_b_ChrgrLOC_Value, sw-syscond=1}
              IN_VeOBCR_b_EnablePowerTransfer_Value: accessed-variable=VeOBCR_b_EnablePowerTransfer.Value, variation-point={short-label=vpIN_VeOBCR_b_EnablePowerTransfer_Value, sw-syscond=1}
              IN_VeOBCR_b_EnblDsblProxPlg_Value: accessed-variable=VeOBCR_b_EnblDsblProxPlg.Value, variation-point={short-label=vpIN_VeOBCR_b_EnblDsblProxPlg_Value, sw-syscond=1}
              IN_VeOBCR_b_PluggedIn_Value: accessed-variable=VeOBCR_b_PluggedIn.Value, variation-point={short-label=vpIN_VeOBCR_b_PluggedIn_Value, sw-syscond=1}
              IN_VeOBCR_b_SecureConnV2L_Value: accessed-variable=VeOBCR_b_SecureConnV2L.Value, variation-point={short-label=vpIN_VeOBCR_b_SecureConnV2L_Value, sw-syscond=1}
              IN_VeOBCR_b_SmartEvse_Dtctd_Value: accessed-variable=VeOBCR_b_SmartEvse_Dtctd.Value, variation-point={short-label=vpIN_VeOBCR_b_SmartEvse_Dtctd_Value, sw-syscond=1}
              IN_VeOBCR_e_ChargeType_Value: accessed-variable=VeOBCR_e_ChargeType.Value, variation-point={short-label=vpIN_VeOBCR_e_ChargeType_Value, sw-syscond=1}
              IN_VeOBCR_e_ChargingLevel_Value: accessed-variable=VeOBCR_e_ChargingLevel.Value, variation-point={short-label=vpIN_VeOBCR_e_ChargingLevel_Value, sw-syscond=1}
              IN_VeOBCR_e_ChrgSysStat_SF_Value: accessed-variable=VeOBCR_e_ChrgSysStat_SF.Value, variation-point={short-label=vpIN_VeOBCR_e_ChrgSysStat_SF_Value, sw-syscond=1}
              IN_VeOFCR_b_ChrgPortOT_StopChrg_Value: accessed-variable=VeOFCR_b_ChrgPortOT_StopChrg.Value, variation-point={short-label=vpIN_VeOFCR_b_ChrgPortOT_StopChrg_Value, sw-syscond=1}
              IN_VeOFCR_k_ChargeReq_Reason_Value: accessed-variable=VeOFCR_k_ChargeReq_Reason.Value, variation-point={short-label=vpIN_VeOFCR_k_ChargeReq_Reason_Value, sw-syscond=1}
              IN_VePMDR_e_PMM_PowerMode_Value: accessed-variable=VePMDR_e_PMM_PowerMode.Value, variation-point={short-label=vpIN_VePMDR_e_PMM_PowerMode_Value, sw-syscond=1}
              IN_VeSCPR_b_ChargeReq_Value: accessed-variable=VeSCPR_b_ChargeReq.Value, variation-point={short-label=vpIN_VeSCPR_b_ChargeReq_Value, sw-syscond=1}
              IN_VeSRAR_k_ReasonStopCharging_Value: accessed-variable=VeSRAR_k_ReasonStopCharging.Value, variation-point={short-label=vpIN_VeSRAR_k_ReasonStopCharging_Value, sw-syscond=1}
          data-send-points:
            20 x access:
              OUT_VeCHFR_b_ChrgSysFault_Value: accessed-variable=VeCHFR_b_ChrgSysFault.Value
              OUT_VeCHFR_U_ChrgVltReqDelta_Value: accessed-variable=VeCHFR_U_ChrgVltReqDelta.Value
              OUT_VeCHFR_k_ChrgSysFault_Reason_Value: accessed-variable=VeCHFR_k_ChrgSysFault_Reason.Value
              OUT_VeCHFR_I_BattSideCurr_Value: accessed-variable=VeCHFR_I_BattSideCurr.Value
              OUT_VeCHFR_b_ChargeReq_ToBPCM_Value: accessed-variable=VeCHFR_b_ChargeReq_ToBPCM.Value
              OUT_VeCHFR_b_ChrgSysFaultBPCM_Value: accessed-variable=VeCHFR_b_ChrgSysFaultBPCM.Value
              OUT_VeCHFR_b_HMIR_MSG5_Value: accessed-variable=VeCHFR_b_HMIR_MSG5.Value
              OUT_VeCHFR_b_HMIR_MSG6_Value: accessed-variable=VeCHFR_b_HMIR_MSG6.Value
              OUT_VeCHFR_b_HMIR_MSG8_Value: accessed-variable=VeCHFR_b_HMIR_MSG8.Value
              OUT_VeCHFR_K_ChargingFailure{1..5}_Value: accessed-variable=VeCHFR_K_ChargingFailure{1..5}.Value
              OUT_VeCHFR_b_ChargingFault_Value: accessed-variable=VeCHFR_b_ChargingFault.Value
              OUT_VeCHFR_b_ACPrnt_S2Open_Value: accessed-variable=VeCHFR_b_ACPrnt_S2Open.Value
              OUT_VeCHFR_v_ModifiedVehSpeed_Value: accessed-variable=VeCHFR_v_ModifiedVehSpeed.Value
              OUT_VeCHFR_b_CANC_WU_NCV_Value: accessed-variable=VeCHFR_b_CANC_WU_NCV.Value
              OUT_VeCHFR_b_Reset_Charging_Value: accessed-variable=VeCHFR_b_Reset_Charging.Value
              OUT_VeCHFR_b_GiveUp_Value: accessed-variable=VeCHFR_b_GiveUp.Value
        CHFR_PwrOff: variation-point={short-label=vpCHFR_PwrOff, sw-syscond=1}
          data-send-points:
            access OUT_EeCHFR_b_ChrgSysFault_EeCHFR_b_ChrgSysFault: accessed-variable=EeCHFR_b_ChrgSysFault.EeCHFR_b_ChrgSysFault, variation-point={short-label=vpOUT_EeCHFR_b_ChrgSysFault_EeCHFR_b_ChrgSysFault, sw-syscond=1}
      variation point proxy Variant_CHFR_1: category=CONDITION, condition-access=1
